# EFM32GG12B810F1024IL112 register map
File version: 4.0.0
CPU: CM4 r0p1, little endian, MPU, FPU, 3 interrupt priority bits
Registers are 32-bit, read-write, reset 0x0 unless marked. A register's access mark holds for its fields unless they carry their own. Offsets are from the block's base; [hi:lo] are bit positions; {n}, {i} and the like mark numbered series; 'fields as' and 'values as' point back to an identical list.

## TIMER0
Base 0x40018000
Same registers: TIMER1 0x40018400, TIMER2 0x40018800, TIMER3 0x40018C00, WTIMER0 0x4001A000, WTIMER1 0x4001A400
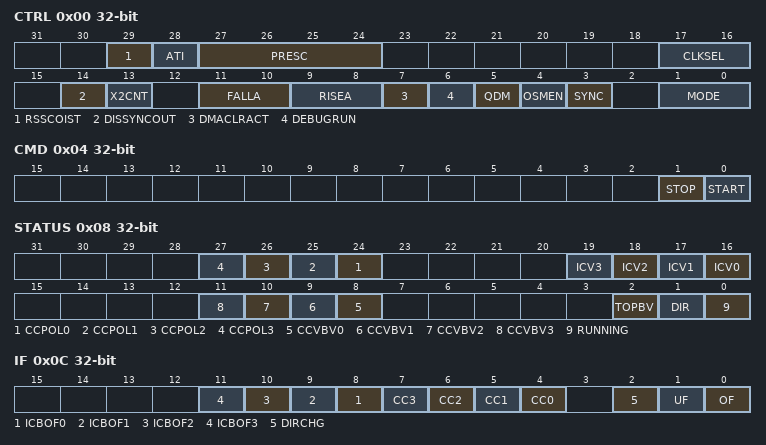
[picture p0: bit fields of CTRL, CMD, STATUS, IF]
0x00 CTRL — Control Register
  [29] RSSCOIST — Reload-Start Sets Compare Output Initial State
  [28] ATI — Always Track Inputs
  [27:24] PRESC — Prescaler Setting
    0=DIV1 (The HFPERCLK is undivided); 1=DIV2 (The HFPERCLK is divided by 2); 2=DIV4 (The HFPERCLK is divided by 4); 3=DIV8 (The HFPERCLK is divided by 8); 4=DIV16 (The HFPERCLK is divided by 16); 5=DIV32 (The HFPERCLK is divided by 32); 6=DIV64 (The HFPERCLK is divided by 64); 7=DIV128 (The HFPERCLK is divided by 128); 8=DIV256 (The HFPERCLK is divided by 256); 9=DIV512 (The HFPERCLK is divided by 512); 10=DIV1024 (The HFPERCLK is divided by 1024)
  [17:16] CLKSEL — Clock Source Select
    0=PRESCHFPERCLK (Prescaled HFPERCLK); 1=CC1 (Compare/Capture Channel 1 Input); 2=TIMEROUF (Timer is clocked by underflow(down-count) or overflow(up-count) in the lower numbered neighbor Timer)
  [14] DISSYNCOUT — Disable Timer From Start/Stop/Reload Other Synchronized Timers
  [13] X2CNT — 2x Count Mode
  [11:10] FALLA — Timer Falling Input Edge Action
    0=NONE (No action); 1=START (Start counter without reload); 2=STOP (Stop counter without reload); 3=RELOADSTART (Reload and start counter)
  [9:8] RISEA — Timer Rising Input Edge Action
    values as FALLA
  [7] DMACLRACT — DMA Request Clear on Active
  [6] DEBUGRUN — Debug Mode Run Enable
  [5] QDM — Quadrature Decoder Mode Selection
  [4] OSMEN — One-shot Mode Enable
  [3] SYNC — Timer Start/Stop/Reload Synchronization
  [1:0] MODE — Timer Mode
    0=UP (Up-count mode); 1=DOWN (Down-count mode); 2=UPDOWN (Up/down-count mode); 3=QDEC (Quadrature decoder mode)
0x04 CMD wo — Command Register
  [1] STOP — Stop Timer
  [0] START — Start Timer
0x08 STATUS ro
  [n+24] CCPOL{n} (n=0..3) — CC{n} Polarity
  [n+16] ICV{n} (n=0..3) — CC{n} Input Capture Valid
  [n+8] CCVBV{n} (n=0..3) — CC{n} CCVB Valid
  [2] TOPBV — TOPB Valid
  [1] DIR — Direction
  [0] RUNNING
0x0C IF ro — Interrupt Flag Register
  [n+8] ICBOF{n} (n=0..3) — CC Channel {n} Input Capture Buffer Overflow Interrupt Flag
  [n+4] CC{n} (n=0..3) — CC Channel {n} Interrupt Flag
  [2] DIRCHG — Direction Change Detect Interrupt Flag
  [1] UF — Underflow Interrupt Flag
  [0] OF — Overflow Interrupt Flag
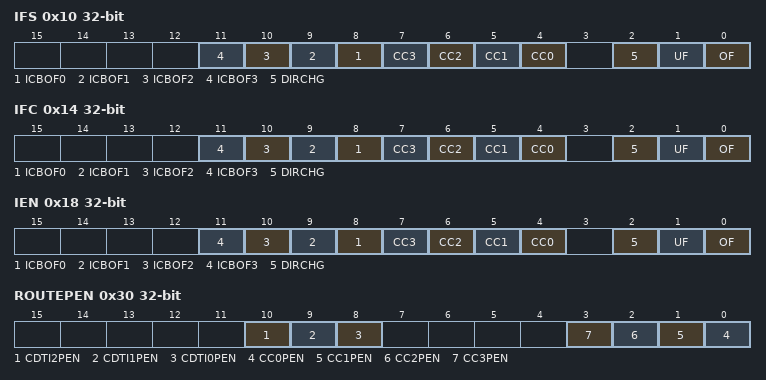
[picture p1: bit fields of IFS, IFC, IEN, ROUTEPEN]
0x10 IFS wo — Interrupt Flag Set Register
  [n+8] ICBOF{n} (n=0..3) — Set ICBOF{n} Interrupt Flag
  [n+4] CC{n} (n=0..3) — Set CC{n} Interrupt Flag
  [2] DIRCHG — Set DIRCHG Interrupt Flag
  [1] UF — Set UF Interrupt Flag
  [0] OF — Set OF Interrupt Flag
0x14 IFC wo — Interrupt Flag Clear Register
  [n+8] ICBOF{n} (n=0..3) — Clear ICBOF{n} Interrupt Flag
  [n+4] CC{n} (n=0..3) — Clear CC{n} Interrupt Flag
  [2] DIRCHG — Clear DIRCHG Interrupt Flag
  [1] UF — Clear UF Interrupt Flag
  [0] OF — Clear OF Interrupt Flag
0x18 IEN — Interrupt Enable Register
  [n+8] ICBOF{n} (n=0..3) — ICBOF{n} Interrupt Enable
  [n+4] CC{n} (n=0..3) — CC{n} Interrupt Enable
  [2] DIRCHG — DIRCHG Interrupt Enable
  [1] UF — UF Interrupt Enable
  [0] OF — OF Interrupt Enable
0x1C TOP reset 0xFFFF — Counter Top Value Register
  [31:0] TOP — Counter Top Value
0x20 TOPB — Counter Top Value Buffer Register
  [31:0] TOPB — Counter Top Value Buffer
0x24 CNT — Counter Value Register
  [31:0] CNT — Counter Value
0x2C LOCK — TIMER Configuration Lock Register
  [15:0] TIMERLOCKKEY
    0=UNLOCKED; 1=LOCKED
0x30 ROUTEPEN — I/O Routing Pin Enable Register
  [10] CDTI2PEN — CC Channel 2 Complementary Dead-Time Insertion Pin Enable
  [9] CDTI1PEN — CC Channel 1 Complementary Dead-Time Insertion Pin Enable
  [8] CDTI0PEN — CC Channel 0 Complementary Dead-Time Insertion Pin Enable
  [n] CC{n}PEN (n=0..3) — CC Channel {n} Pin Enable
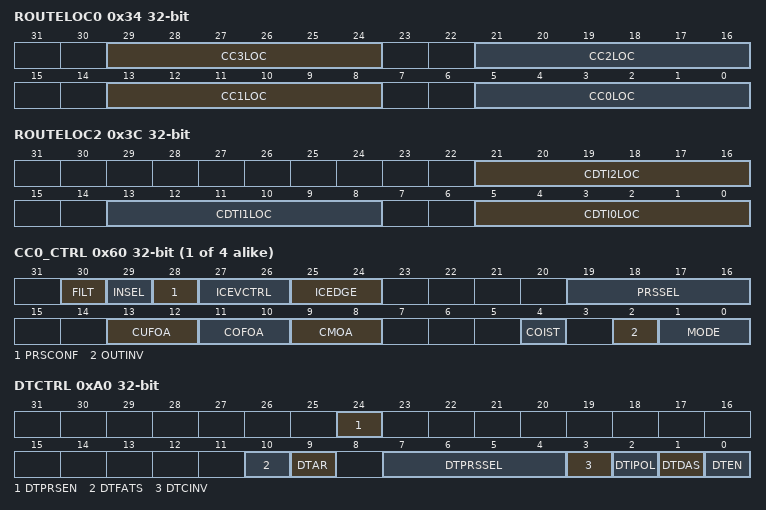
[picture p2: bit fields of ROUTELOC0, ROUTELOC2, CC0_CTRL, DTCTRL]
0x34 ROUTELOC0 — I/O Routing Location Register
  [29:24] CC3LOC — I/O Location
    {v}=LOC{v} (Location {v}) (v=0..6)
  [21:16] CC2LOC — I/O Location
    {v}=LOC{v} (Location {v}) (v=0..7)
  [13:8] CC1LOC — I/O Location
    {v}=LOC{v} (Location {v}) (v=0..7)
  [5:0] CC0LOC — I/O Location
    {v}=LOC{v} (Location {v}) (v=0..7)
0x3C ROUTELOC2 — I/O Routing Location Register
  [all] fields
    {v}=LOC{v} (Location {v}) (v=0..4)
  [21:16] CDTI2LOC — I/O Location
  [13:8] CDTI1LOC — I/O Location
  [5:0] CDTI0LOC — I/O Location
{0x60+0x10*i} CC{i}_CTRL (i=0..3) — CC Channel Control Register
  [30] FILT — Digital Filter
  [29] INSEL — Input Selection
  [28] PRSCONF — PRS Configuration
  [27:26] ICEVCTRL — Input Capture Event Control
    0=EVERYEDGE (PRS output pulse and interrupt flag set on every capture); 1=EVERYSECONDEDGE (PRS output pulse and interrupt flag set on every second capture); 2=RISING (PRS output pulse and interrupt flag set on rising edge only (if ICEDGE = BOTH)); 3=FALLING (PRS output pulse and interrupt flag set on falling edge only (if ICEDGE = BOTH))
  [25:24] ICEDGE — Input Capture Edge Select
    0=RISING (Rising edges detected); 1=FALLING (Falling edges detected); 2=BOTH (Both edges detected); 3=NONE (No edge detection, signal is left as it is)
  [19:16] PRSSEL — Compare/Capture Channel PRS Input Channel Selection
    {v}=PRSCH{v} (PRS Channel {v} selected as input) (v=0..15)
  [13:12] CUFOA — Counter Underflow Output Action
    0=NONE (No action on counter underflow); 1=TOGGLE (Toggle output on counter underflow); 2=CLEAR (Clear output on counter underflow); 3=SET (Set output on counter underflow)
  [11:10] COFOA — Counter Overflow Output Action
    0=NONE (No action on counter overflow); 1=TOGGLE (Toggle output on counter overflow); 2=CLEAR (Clear output on counter overflow); 3=SET (Set output on counter overflow)
  [9:8] CMOA — Compare Match Output Action
    0=NONE (No action on compare match); 1=TOGGLE (Toggle output on compare match); 2=CLEAR (Clear output on compare match); 3=SET (Set output on compare match)
  [4] COIST — Compare Output Initial State
  [2] OUTINV — Output Invert
  [1:0] MODE — CC Channel Mode
    0=OFF (Compare/Capture channel turned off); 1=INPUTCAPTURE; 2=OUTPUTCOMPARE; 3=PWM (Pulse-Width Modulation)
{0x64+0x10*i} CC{i}_CCV read-has-side-effects (i=0..3) — CC Channel Value Register
  [31:0] CCV — CC Channel Value
{0x68+0x10*i} CC{i}_CCVP ro (i=0..3) — CC Channel Value Peek Register
  [31:0] CCVP — CC Channel Value Peek
{0x6C+0x10*i} CC{i}_CCVB (i=0..3) — CC Channel Buffer Register
  [31:0] CCVB — CC Channel Value Buffer
0xA0 DTCTRL — DTI Control Register
  [24] DTPRSEN — DTI PRS Source Enable
  [10] DTFATS — DTI Fault Action on Timer Stop
  [9] DTAR — DTI Always Run
  [7:4] DTPRSSEL — DTI PRS Source Channel Select
    {v}=PRSCH{v} (PRS Channel {v} selected as input) (v=0..15)
  [3] DTCINV — DTI Complementary Output Invert
  [2] DTIPOL — DTI Inactive Polarity
  [1] DTDAS — DTI Automatic Start-up Functionality
  [0] DTEN — DTI Enable
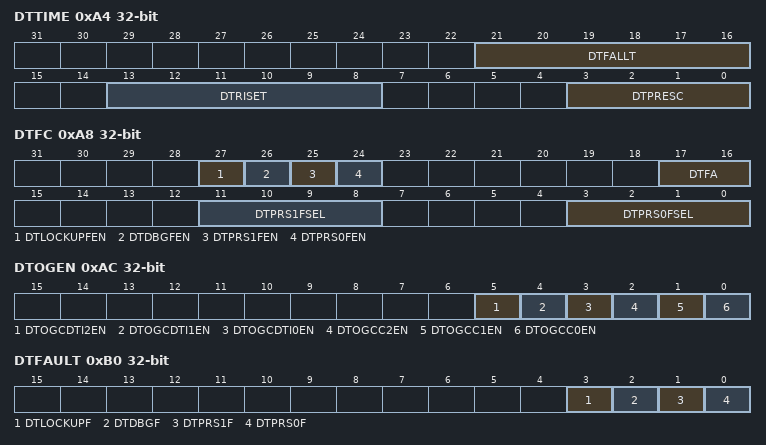
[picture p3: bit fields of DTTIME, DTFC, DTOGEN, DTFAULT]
0xA4 DTTIME — DTI Time Control Register
  [21:16] DTFALLT — DTI Fall-time
  [13:8] DTRISET — DTI Rise-time
  [3:0] DTPRESC — DTI Prescaler Setting
    values as CTRL.PRESC
0xA8 DTFC — DTI Fault Configuration Register
  [27] DTLOCKUPFEN — DTI Lockup Fault Enable
  [26] DTDBGFEN — DTI Debugger Fault Enable
  [25] DTPRS1FEN — DTI PRS 1 Fault Enable
  [24] DTPRS0FEN — DTI PRS 0 Fault Enable
  [17:16] DTFA — DTI Fault Action
    0=NONE (No action on fault); 1=INACTIVE (Set outputs inactive); 2=CLEAR (Clear outputs); 3=TRISTATE (Tristate outputs)
  [11:8] DTPRS1FSEL — DTI PRS Fault Source 1 Select
    {v}=PRSCH{v} (PRS Channel {v} selected as fault source 1) (v=0..15)
  [3:0] DTPRS0FSEL — DTI PRS Fault Source 0 Select
    {v}=PRSCH{v} (PRS Channel {v} selected as fault source {v}) (v=0..15)
0xAC DTOGEN — DTI Output Generation Enable Register
  [5] DTOGCDTI2EN — DTI CDTI2 Output Generation Enable
  [4] DTOGCDTI1EN — DTI CDTI1 Output Generation Enable
  [3] DTOGCDTI0EN — DTI CDTI0 Output Generation Enable
  [2] DTOGCC2EN — DTI CC2 Output Generation Enable
  [1] DTOGCC1EN — DTI CC1 Output Generation Enable
  [0] DTOGCC0EN — DTI CC0 Output Generation Enable
0xB0 DTFAULT ro — DTI Fault Register
  [3] DTLOCKUPF — DTI Lockup Fault
  [2] DTDBGF — DTI Debugger Fault
  [1] DTPRS1F — DTI PRS 1 Fault
  [0] DTPRS0F — DTI PRS 0 Fault
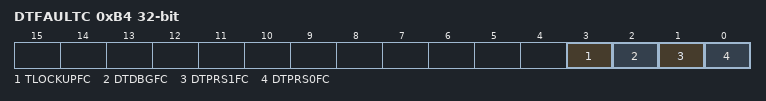
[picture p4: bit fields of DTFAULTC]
0xB4 DTFAULTC wo — DTI Fault Clear Register
  [3] TLOCKUPFC — DTI Lockup Fault Clear
  [2] DTDBGFC — DTI Debugger Fault Clear
  [1] DTPRS1FC — DTI PRS1 Fault Clear
  [0] DTPRS0FC — DTI PRS0 Fault Clear
0xB8 DTLOCK — DTI Configuration Lock Register
  [15:0] LOCKKEY — DTI Lock Key
    0=UNLOCKED; 1=LOCKED

## Notices in the file
# License
Copyright 2021 Silicon Laboratories Inc. www.silabs.com
SPDX-License-Identifier: Zlib
The licensor of this software is Silicon Laboratories Inc.
This software is provided 'as-is', without any express or implied
warranty. In no event will the authors be held liable for any damages
arising from the use of this software.
Permission is granted to anyone to use this software for any purpose,
including commercial applications, and to alter it and redistribute it
freely, subject to the following restrictions:
1. The origin of this software must not be misrepresented; you must not
claim that you wrote the original software. If you use this software
in a product, an acknowledgment in the product documentation would be
appreciated but is not required.
2. Altered source versions must be plainly marked as such, and must not be
misrepresented as being the original software.
3. This notice may not be removed or altered from any source distribution.
